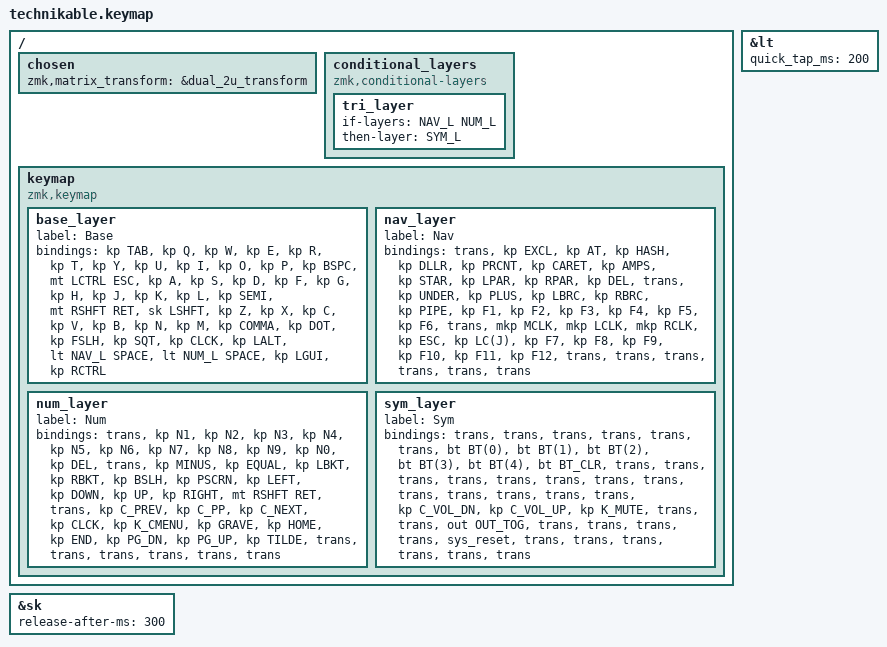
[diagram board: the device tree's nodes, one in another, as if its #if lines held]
/*
 * Copyright (c) 2022 Pete Johanson
 *
 * SPDX-License-Identifier: MIT
 */

#include <behaviors.dtsi>
#include <dt-bindings/zmk/keys.h>
#include <dt-bindings/zmk/bt.h>
#include <dt-bindings/zmk/outputs.h>
#include <dt-bindings/zmk/mouse.h>

// #define QWERTY_BASE 1

// #define TBLE_ORTHO   true
#define TBLE_MIT     true
// #define TBLE_DUAL_2U true

#define BAS_L 0
#define NAV_L 1
#define NUM_L 2
#define SYM_L 3

// Using layer taps on thumbs, having quick tap as well helps w/ repeating space/backspace
&lt { quick_tap_ms = <200>; };

&sk { release-after-ms = <300>; };

#define BT(n) BT_SEL n

/ {
    chosen {
        zmk,matrix_transform =
#ifdef TBLE_DUAL_2U
                       &dual_2u_transform;
#elif defined(TBLE_MIT)
                       &mit_transform;
#else
                       &ortho_transform;
#endif
    };

    conditional_layers {
        compatible = "zmk,conditional-layers";
        tri_layer {
            if-layers = <NAV_L NUM_L>;
            then-layer = <SYM_L>;
        };
    };

    keymap {
        compatible = "zmk,keymap";

        base_layer {
            label = "Base";
            bindings = <
#ifdef QWERTY_BASE
 &kp TAB          &kp Q      &kp W      &kp E       &kp R          &kp T          &kp Y            &kp U          &kp I       &kp O      &kp P         &kp BSPC
 &mt LCTRL ESC    &kp A      &kp S      &kp D       &kp F          &kp G          &kp H            &kp J          &kp K       &kp L      &kp SEMI      &mt RSHFT RET
 &sk LSHFT        &kp Z      &kp X      &kp C       &kp V          &kp B          &kp N            &kp M          &kp COMMA   &kp DOT    &kp FSLH      &kp SQT
#else
 &kp TAB          &kp Q      &kp W      &kp F       &kp P          &kp B          &kp J            &kp L          &kp U       &kp Y      &kp SEMI     &kp BSPC
 &mt LCTRL ESC    &kp A      &kp R      &kp S       &kp T          &kp G          &kp M            &kp N          &kp E       &kp I      &kp O        &mt RSHFT RET
 &sk LSHFT        &kp Z      &kp X      &kp C       &kp D          &kp V          &kp K            &kp H          &kp COMMA   &kp DOT    &kp FSLH     &kp SQT
#endif
#ifdef TBLE_DUAL_2U
                       &kp CLCK  &kp LALT      &lt NAV_L SPACE                &lt NUM_L SPACE              &kp LGUI    &kp RCTRL
#elif defined(TBLE_MIT)
                       &kp CLCK  &kp LALT    &mo NAV_L          &kp SPACE                   &mo NUM_L      &kp LGUI    &kp RCTRL
#else
                       &kp CLCK  &kp LALT    &mo NAV_L      &kp SPACE      &kp SPACE        &mo NUM_L      &kp LGUI    &kp RCTRL
#endif
            >;
        };

        nav_layer {
            label = "Nav";
            bindings = <
&trans     &kp EXCL      &kp AT        &kp HASH      &kp DLLR          &kp PRCNT    &kp CARET  &kp AMPS     &kp STAR  &kp LPAR     &kp RPAR   &kp DEL
&trans     &kp UNDER     &kp PLUS      &kp LBRC      &kp RBRC          &kp PIPE     &kp F1     &kp F2       &kp F3    &kp F4       &kp F5     &kp F6
&trans     &mkp MCLK     &mkp LCLK     &mkp RCLK     &kp ESC           &kp LC(J)    &kp F7     &kp F8       &kp F9    &kp F10      &kp F11    &kp F12
#ifdef TBLE_DUAL_2U
                      &trans     &trans              &trans                    &trans       &trans         &trans
#elif defined(TBLE_MIT)
                      &trans     &trans      &trans                &trans             &trans      &trans   &trans
#else
                      &trans     &trans      &trans          &trans       &trans    &trans  &trans         &trans
#endif
            >;
        };

        num_layer {
            label = "Num";
            bindings = <
&trans     &kp N1      &kp N2       &kp N3       &kp N4      &kp N5         &kp N6      &kp N7         &kp N8       &kp N9       &kp N0        &kp DEL
&trans     &kp MINUS   &kp EQUAL    &kp LBKT     &kp RBKT    &kp BSLH       &kp PSCRN   &kp LEFT       &kp DOWN     &kp UP       &kp RIGHT     &mt RSHFT RET
&trans     &kp C_PREV  &kp C_PP     &kp C_NEXT   &kp CLCK    &kp K_CMENU    &kp GRAVE   &kp HOME       &kp END      &kp PG_DN    &kp PG_UP     &kp TILDE
#ifdef TBLE_DUAL_2U
                     &trans     &trans              &trans                 &trans            &trans         &trans
#elif defined(TBLE_MIT)
                     &trans     &trans      &trans           &trans            &trans        &trans      &trans
#else
                     &trans     &trans      &trans    &trans         &trans     &trans        &trans      &trans
#endif
            >;
        };

        sym_layer {
            label = "Sym";
            bindings = <
&trans     &trans         &trans        &trans      &trans   &trans     &bt BT(0)     &bt BT(1)    &bt BT(2)    &bt BT(3)    &bt BT(4)  &bt BT_CLR
&trans     &trans         &trans        &trans      &trans   &trans     &trans        &trans       &trans       &trans       &trans     &trans
&trans     &kp C_VOL_DN   &kp C_VOL_UP  &kp K_MUTE  &trans   &trans     &out OUT_TOG  &trans       &trans       &trans       &trans     &sys_reset
#ifdef TBLE_DUAL_2U
                      &trans     &trans              &trans                    &trans       &trans         &trans
#elif defined(TBLE_MIT)
                      &trans     &trans      &trans                &trans             &trans      &trans   &trans
#else
                      &trans     &trans      &trans          &trans       &trans    &trans  &trans         &trans
#endif
            >;
        };

    };
};

